# rCSL_hpi_001 register map
Vendor: Texas Instruments
Peripheral module from a debugger description file (folder c674x).
Registers are 32-bit, access not given, reset 0x8000 unless marked. A register's access mark holds for its fields unless they carry their own. Offsets are as the file gives them; lines under a group give offsets from that group; [hi:lo] are bit positions; {n}, {i} and the like mark numbered series; 'fields as' and 'values as' point back to an identical list; <NAME> marks a mode.

## HPI
0x00 REVID ro reset 0x4421210A — Revision ID
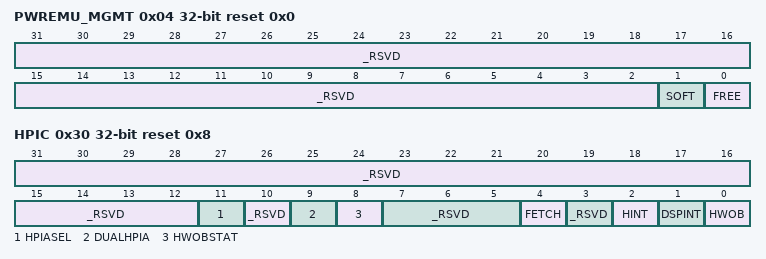
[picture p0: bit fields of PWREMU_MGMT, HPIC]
0x04 PWREMU_MGMT reset 0x0 — Power Management and Emulation
  [31:2] _RSVD — (access N)
  [1] SOFT rw — SOFT; 0=Normal Mode, 1=EMU Suspend
    0=OFF; 1=ON
  [0] FREE rw — FREE; 0=Use SOFT, 1=Normal Mode
    0=OFF; 1=ON
0x30 HPIC reset 0x8 — Host Port Interface Control
  [31:12] _RSVD — (access N)
  [11] HPIASEL rw — HPIA Register Select Bit
    0=WRITE; 1=READ
  [10] _RSVD — (access N)
  [9] DUALHPIA rw — Dual HPI Mode
    0=DISABLE; 1=ENABLE
  [8] HWOBSTAT ro — HWOB Status
    0=LOGIC0; 1=LOGIC1
  [7:5] _RSVD — (access N)
  [4] FETCH rw — Host data fetch request
  [3] _RSVD — (access N)
  [2] HINT rw — DSP-to-host interrupt
    1=ENABLE
  [1] DSPINT rw — Host-to-DSP interrupt
    1=ENABLE
  [0] HWOB rw — Half-word Ordering Bit
    0=MS; 1=LS
0x34 HPIAW rw — Host Port Interface Address Write
  [31:0] HPIAW — Address of CPU memory space to be written
0x38 HPIAR rw — Host Port Interface Address Read
  [31:0] HPIAR — Address of CPU memory space to be read
